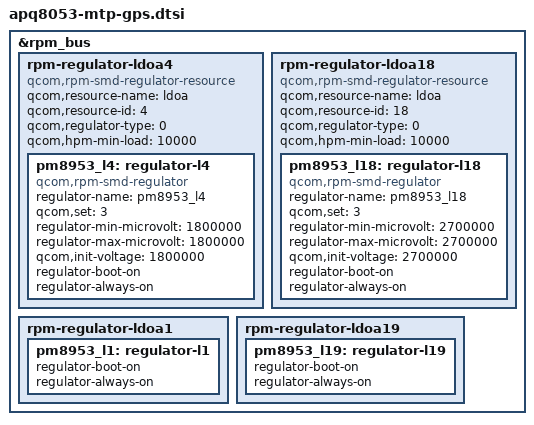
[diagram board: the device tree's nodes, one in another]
/* Copyright (c) 2015-2016, The Linux Foundation. All rights reserved.
 *
 * This program is free software; you can redistribute it and/or modify
 * it under the terms of the GNU General Public License version 2 and
 * only version 2 as published by the Free Software Foundation.
 *
 * This program is distributed in the hope that it will be useful,
 * but WITHOUT ANY WARRANTY; without even the implied warranty of
 * MERCHANTABILITY or FITNESS FOR A PARTICULAR PURPOSE.  See the
 * GNU General Public License for more details.
 */
/* 2017/03/31, Jerry Zhai, add this file to Enable GPS function */

&rpm_bus {
	rpm-regulator-ldoa4 {
		compatible = "qcom,rpm-smd-regulator-resource";
		qcom,resource-name = "ldoa";
		qcom,resource-id = <4>;
		qcom,regulator-type = <0>;
		qcom,hpm-min-load = <10000>;
		status = "disabled";

		regulator-l4 {
			compatible = "qcom,rpm-smd-regulator";
			regulator-name = "pm8953_l4";
			qcom,set = <3>;
			status = "disabled";
		};
	};

	rpm-regulator-ldoa18 {
		compatible = "qcom,rpm-smd-regulator-resource";
		qcom,resource-name = "ldoa";
		qcom,resource-id = <18>;
		qcom,regulator-type = <0>;
		qcom,hpm-min-load = <10000>;
		status = "disabled";

		regulator-l18 {
			compatible = "qcom,rpm-smd-regulator";
			regulator-name = "pm8953_l18";
			qcom,set = <3>;
			status = "disabled";
		};
	};

	rpm-regulator-ldoa1 {
		pm8953_l1: regulator-l1 {
			regulator-boot-on;
			regulator-always-on;
		};
	};

	rpm-regulator-ldoa4 {
		status = "okay";
		pm8953_l4: regulator-l4 {
			regulator-min-microvolt = <1800000>;
			regulator-max-microvolt = <1800000>;
			qcom,init-voltage = <1800000>;
			regulator-boot-on;
			regulator-always-on;
			status = "okay";
		};
	};

	rpm-regulator-ldoa18 {
		status = "okay";
		pm8953_l18: regulator-l18 {
			regulator-min-microvolt = <2700000>;
			regulator-max-microvolt = <2700000>;
			qcom,init-voltage = <2700000>;
			regulator-boot-on;
			regulator-always-on;
			status = "okay";
		};
	};

	rpm-regulator-ldoa19 {
		pm8953_l19: regulator-l19 {
			regulator-boot-on;
			regulator-always-on;
		};
	};
};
